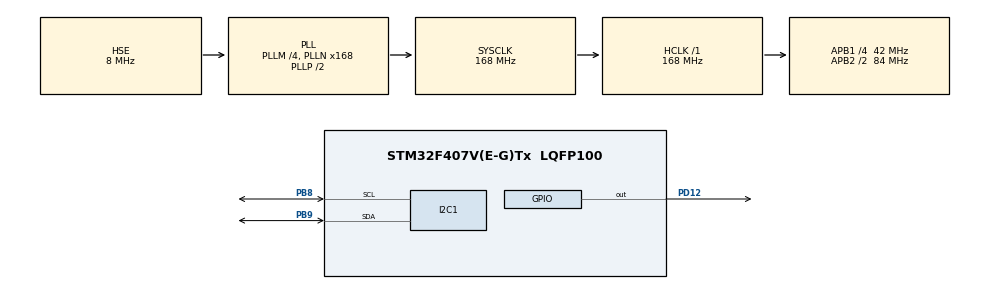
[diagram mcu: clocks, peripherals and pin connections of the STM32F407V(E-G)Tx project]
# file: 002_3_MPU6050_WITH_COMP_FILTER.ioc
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I2C1.I2C_Mode=I2C_Fast
Mcu.Family=STM32F4
Mcu.Name=STM32F407V(E-G)Tx
Mcu.Package=LQFP100
NVIC.PriorityGroup=NVIC_PRIORITYGROUP_4
PB8.Mode=I2C
PB8.Signal=I2C1_SCL
PB9.Mode=I2C
PB9.Signal=I2C1_SDA
PD12.Signal=GPIO_Output
PH0-OSC_IN.Mode=HSE-External-Oscillator
PH0-OSC_IN.Signal=RCC_OSC_IN
PH1-OSC_OUT.Mode=HSE-External-Oscillator
PH1-OSC_OUT.Signal=RCC_OSC_OUT
ProjectManager.HeapSize=0x200
ProjectManager.StackSize=0x400
ProjectManager.TargetToolchain=STM32CubeIDE
RCC.48MHZClocksFreq_Value=84000000
RCC.AHBFreq_Value=168000000
RCC.APB1CLKDivider=RCC_HCLK_DIV4
RCC.APB1Freq_Value=42000000
RCC.APB1TimFreq_Value=84000000
RCC.APB2CLKDivider=RCC_HCLK_DIV2
RCC.APB2Freq_Value=84000000
RCC.APB2TimFreq_Value=168000000
RCC.CortexFreq_Value=168000000
RCC.HCLKFreq_Value=168000000
RCC.HSE_VALUE=8000000
RCC.HSI_VALUE=16000000
RCC.LSE_VALUE=32768
RCC.PLLM=4
RCC.PLLN=168
RCC.PLLSourceVirtual=RCC_PLLSOURCE_HSE
RCC.SYSCLKFreq_VALUE=168000000
RCC.SYSCLKSource=RCC_SYSCLKSOURCE_PLLCLK
RCC.VCOOutputFreq_Value=336000000
board=custom

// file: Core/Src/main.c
/* USER CODE BEGIN Header */
/**
  ******************************************************************************
  * @file           : main.c
  * @brief          : Main program body
  ******************************************************************************
  * @attention
  *
  * Copyright (c) 2023 STMicroelectronics.
  * All rights reserved.
  *
  * This software is licensed under terms that can be found in the LICENSE file
  * in the root directory of this software component.
  * If no LICENSE file comes with this software, it is provided AS-IS.
  *
  ******************************************************************************
  */
/* USER CODE END Header */
#include "main.h"

/* USER CODE BEGIN Includes */
#include "stdio.h"
#include "string.h"
#include "stdlib.h"
#include "math.h"
#include "stdbool.h"
/* USER CODE END Includes */

/* USER CODE BEGIN PD */
#define MPU6050_ADDR 0x68<<1
#define PWR_MGMT_1_REG 0x6B
#define SMPLRT_DIV_REG 0x19
#define GYRO_CNFG_REG 0x1B
#define ACC_CNFG_REG 0x1C
/* USER CODE END PD */

I2C_HandleTypeDef hi2c1;

/* USER CODE BEGIN PV */
uint8_t data;
uint8_t Temp_buffer[2], Acc_buffer[6], Gyro_buffer[6]; //raw data list
int16_t gyro_raw[3], acc_raw[3]; // processed data list
float gyro_cal[3]; // calibration offsets
int16_t acc_total_vector;
float angle_pitch_gyro, angle_roll_gyro;
float angle_pitch_acc, angle_roll_acc;
float angle_pitch, angle_roll;
int16_t raw_temp;
float temp;
int i;
float pTime, pTime1, time1, elapsedtime1, pTime2, time2, elapsedtime2;
HAL_StatusTypeDef setgyro;

/* USER CODE END PV */

void SystemClock_Config(void);
static void MX_GPIO_Init(void);
static void MX_I2C1_Init(void);

int main(void)
{

  /* MCU Configuration--------------------------------------------------------*/

  /* Reset of all peripherals, Initializes the Flash interface and the Systick. */
  HAL_Init();

  /* Configure the system clock */
  SystemClock_Config();

  /* Initialize all configured peripherals */
  MX_GPIO_Init();
  MX_I2C1_Init();
  /* USER CODE BEGIN 2 */

  data = 0x00;
  HAL_I2C_Mem_Write(&hi2c1, MPU6050_ADDR, PWR_MGMT_1_REG, 1, &data, 1, HAL_MAX_DELAY);

  //GYRO_CONFIG => +-500 DERECE/SANIYE -----> 08
  data = 0x08;
  HAL_I2C_Mem_Write(&hi2c1, MPU6050_ADDR, GYRO_CNFG_REG, 1, &data, 1, HAL_MAX_DELAY);

  //ACC_CONFIG => +-8G ------> 10
  data = 0x10;
  HAL_I2C_Mem_Write(&hi2c1, MPU6050_ADDR, ACC_CNFG_REG, 1, &data, 1, HAL_MAX_DELAY);

  for(i=0 ; i<2000 ; i++)
  {
	  pTime2 = time2;
	  time2 = HAL_GetTick();
	  elapsedtime2 = (time2 - pTime2) * 1000;

	  Gyro_buffer[0] = 0x43;
	  HAL_I2C_Master_Transmit(&hi2c1, MPU6050_ADDR, Gyro_buffer, 1, HAL_MAX_DELAY);
	  HAL_I2C_Master_Receive(&hi2c1, MPU6050_ADDR, Gyro_buffer, 6, HAL_MAX_DELAY);

	  gyro_raw[0] = (Gyro_buffer[0] << 8 | Gyro_buffer[1]); //X ekseni
	  gyro_raw[1] = (Gyro_buffer[2] << 8 | Gyro_buffer[3]); //Y ekseni
	  gyro_raw[2] = (Gyro_buffer[4] << 8 | Gyro_buffer[5]); //Z ekseni

	  gyro_cal[0] += gyro_raw[0];
	  gyro_cal[1] += gyro_raw[1];
	  gyro_cal[2] += gyro_raw[2];

	  HAL_Delay(3); // 4 ms
  }

  gyro_cal[0] /= 2000;
  gyro_cal[1] /= 2000;
  gyro_cal[2] /= 2000;

  HAL_GPIO_TogglePin(GPIOD, GPIO_PIN_12);
  HAL_Delay(1000);

  /* USER CODE END 2 */

  /* Infinite loop */
  /* USER CODE BEGIN WHILE */
  while (1)
  {
	  pTime1 = time1;
	  time1 = HAL_GetTick();
	  elapsedtime1 = (time1 - pTime1)*1000;

	  Acc_buffer[0] = 0x3B;
	  HAL_I2C_Master_Transmit(&hi2c1, MPU6050_ADDR, Acc_buffer, 1, HAL_MAX_DELAY);
	  HAL_I2C_Master_Receive(&hi2c1, MPU6050_ADDR, Acc_buffer, 6, HAL_MAX_DELAY);

	  //Acc raw values
	  acc_raw[0] = (Acc_buffer[0] << 8 | Acc_buffer[1]);
	  acc_raw[1] = (Acc_buffer[2] << 8 | Acc_buffer[3]);
	  acc_raw[2] = (Acc_buffer[4] << 8 | Acc_buffer[5]);

	  Temp_buffer[0] = 0x41;
	  HAL_I2C_Master_Transmit(&hi2c1, MPU6050_ADDR, Temp_buffer, 1, HAL_MAX_DELAY);
	  HAL_I2C_Master_Receive(&hi2c1, MPU6050_ADDR, Temp_buffer, 2, HAL_MAX_DELAY);

	  raw_temp = (Temp_buffer[0] << 8 | Temp_buffer[1]);
	  temp = (temp / 340.0) + 36.53;

	  Gyro_buffer[0] = 0x43;
	  HAL_I2C_Master_Transmit(&hi2c1, MPU6050_ADDR, Gyro_buffer, 1, HAL_MAX_DELAY);
	  HAL_I2C_Master_Receive(&hi2c1, MPU6050_ADDR, Gyro_buffer, 6, HAL_MAX_DELAY);

	  //Gyro raw values
	  gyro_raw[0] = (Gyro_buffer[0] << 8 | Gyro_buffer[1]);
	  gyro_raw[1] = (Gyro_buffer[2] << 8 | Gyro_buffer[3]);
	  gyro_raw[2] = (Gyro_buffer[4] << 8 | Gyro_buffer[5]);

	  gyro_raw[0] -= gyro_cal[0];
	  gyro_raw[1] -= gyro_cal[1];
	  gyro_raw[2] -= gyro_cal[2];

	  angle_pitch_gyro += gyro_raw[0] * 0.0000611;
	  angle_roll_gyro += gyro_raw[1] * 0.0000611;

	  angle_pitch_gyro += angle_roll_gyro * sin(gyro_raw[2] * 0.000001066);
	  angle_roll_gyro -= angle_pitch_gyro * sin(gyro_raw[2] * 0.000001066);

	  acc_total_vector = sqrt((acc_raw[0]*acc_raw[0]) + (acc_raw[1]*acc_raw[1]) + (acc_raw[2]*acc_raw[2]));

	  //57.296 = 1 / (3.142 / 180) //derece/saniye hesabi
	  angle_pitch_acc = asin((float)acc_raw[1]/acc_total_vector) * 57.296;
	  angle_roll_acc = asin((float)acc_raw[0]/acc_total_vector) * -57.296;

	  //calibration offsets
	  angle_pitch_acc -= 0.00;
	  angle_roll_acc -= 0.00;

	  if(setgyro)
	  {
		  angle_pitch = angle_pitch_gyro * 0.9996 + angle_pitch_acc * 0.0004;
		  angle_roll = angle_roll_gyro * 0.9996 + angle_roll_acc * 0.0004;
	  }
	  else
	  {
		  angle_pitch = angle_pitch_acc;
		  setgyro = true;
	  }

	  while((HAL_GetTick() - pTime) * 1000 < 4000);
	  pTime = HAL_GetTick();

    /* USER CODE END WHILE */

  }
}

void SystemClock_Config(void)
{
  RCC_OscInitTypeDef RCC_OscInitStruct = {0};
  RCC_ClkInitTypeDef RCC_ClkInitStruct = {0};

  /** Configure the main internal regulator output voltage
  */
  __HAL_RCC_PWR_CLK_ENABLE();
  __HAL_PWR_VOLTAGESCALING_CONFIG(PWR_REGULATOR_VOLTAGE_SCALE1);

  /** Initializes the RCC Oscillators according to the specified parameters
  * in the RCC_OscInitTypeDef structure.
  */
  RCC_OscInitStruct.OscillatorType = RCC_OSCILLATORTYPE_HSE;
  RCC_OscInitStruct.HSEState = RCC_HSE_ON;
  RCC_OscInitStruct.PLL.PLLState = RCC_PLL_ON;
  RCC_OscInitStruct.PLL.PLLSource = RCC_PLLSOURCE_HSE;
  RCC_OscInitStruct.PLL.PLLM = 4;
  RCC_OscInitStruct.PLL.PLLN = 168;
  RCC_OscInitStruct.PLL.PLLP = RCC_PLLP_DIV2;
  RCC_OscInitStruct.PLL.PLLQ = 4;
  if (HAL_RCC_OscConfig(&RCC_OscInitStruct) != HAL_OK)
  {
    Error_Handler();
  }

  /** Initializes the CPU, AHB and APB buses clocks
  */
  RCC_ClkInitStruct.ClockType = RCC_CLOCKTYPE_HCLK|RCC_CLOCKTYPE_SYSCLK
                              |RCC_CLOCKTYPE_PCLK1|RCC_CLOCKTYPE_PCLK2;
  RCC_ClkInitStruct.SYSCLKSource = RCC_SYSCLKSOURCE_PLLCLK;
  RCC_ClkInitStruct.AHBCLKDivider = RCC_SYSCLK_DIV1;
  RCC_ClkInitStruct.APB1CLKDivider = RCC_HCLK_DIV4;
  RCC_ClkInitStruct.APB2CLKDivider = RCC_HCLK_DIV2;

  if (HAL_RCC_ClockConfig(&RCC_ClkInitStruct, FLASH_LATENCY_5) != HAL_OK)
  {
    Error_Handler();
  }
}

static void MX_I2C1_Init(void)
{

  hi2c1.Instance = I2C1;
  hi2c1.Init.ClockSpeed = 400000;
  hi2c1.Init.DutyCycle = I2C_DUTYCYCLE_2;
  hi2c1.Init.OwnAddress1 = 0;
  hi2c1.Init.AddressingMode = I2C_ADDRESSINGMODE_7BIT;
  hi2c1.Init.DualAddressMode = I2C_DUALADDRESS_DISABLE;
  hi2c1.Init.OwnAddress2 = 0;
  hi2c1.Init.GeneralCallMode = I2C_GENERALCALL_DISABLE;
  hi2c1.Init.NoStretchMode = I2C_NOSTRETCH_DISABLE;
  if (HAL_I2C_Init(&hi2c1) != HAL_OK)
  {
    Error_Handler();
  }

}

static void MX_GPIO_Init(void)
{
  GPIO_InitTypeDef GPIO_InitStruct = {0};

  /* GPIO Ports Clock Enable */
  __HAL_RCC_GPIOH_CLK_ENABLE();
  __HAL_RCC_GPIOD_CLK_ENABLE();
  __HAL_RCC_GPIOB_CLK_ENABLE();

  /*Configure GPIO pin Output Level */
  HAL_GPIO_WritePin(GPIOD, GPIO_PIN_12, GPIO_PIN_RESET);

  /*Configure GPIO pin : PD12 */
  GPIO_InitStruct.Pin = GPIO_PIN_12;
  GPIO_InitStruct.Mode = GPIO_MODE_OUTPUT_PP;
  GPIO_InitStruct.Pull = GPIO_NOPULL;
  GPIO_InitStruct.Speed = GPIO_SPEED_FREQ_LOW;
  HAL_GPIO_Init(GPIOD, &GPIO_InitStruct);

}

void Error_Handler(void)
{
  __disable_irq();
  while (1)
  {
  }
}
